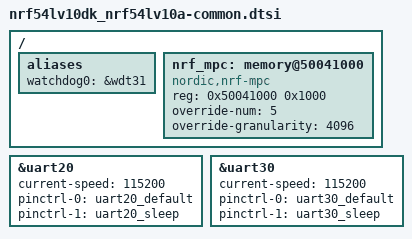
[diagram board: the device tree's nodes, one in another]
/*
 * Copyright (c) 2025 Nordic Semiconductor ASA
 *
 * SPDX-License-Identifier: LicenseRef-Nordic-5-Clause
 */

#include "nrf54lv10dk_nrf54lv10a-pinctrl.dtsi"

/ {
	aliases {
		watchdog0 = &wdt31;
	};

	nrf_mpc: memory@50041000 {
		compatible = "nordic,nrf-mpc";
		reg = <0x50041000 0x1000>;
		#address-cells = <1>;
		#size-cells = <1>;
		override-num = <5>;
		override-granularity = <4096>;
	};
};

&uart20 {
	current-speed = <115200>;
	pinctrl-0 = <&uart20_default>;
	pinctrl-1 = <&uart20_sleep>;
	pinctrl-names = "default", "sleep";
};

&uart30 {
	current-speed = <115200>;
	pinctrl-0 = <&uart30_default>;
	pinctrl-1 = <&uart30_sleep>;
	pinctrl-names = "default", "sleep";
};
